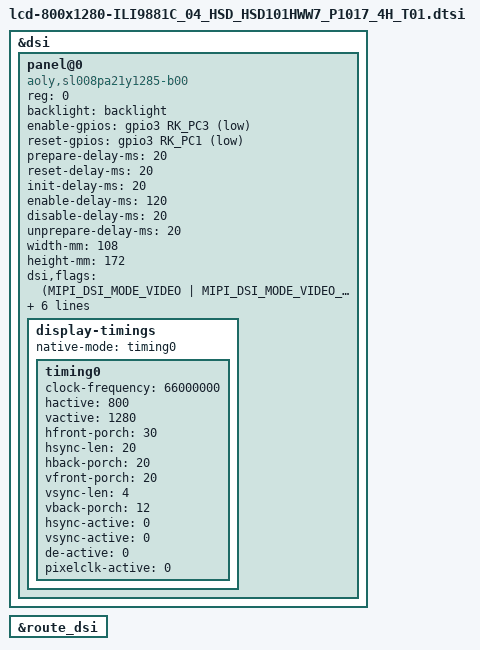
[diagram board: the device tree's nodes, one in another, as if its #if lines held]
&dsi {
	status = "okay";

	panel@0 {
		compatible = "aoly,sl008pa21y1285-b00", "simple-panel-dsi";
		reg = <0>;
		backlight = <&backlight>;
	//	power-supply = <&vcc5v0_host>;//vcc5v0_host  vcc3v3_lcd
	//	power-invert;
#if defined (DHTX_CFP3310M1A)
		enable-gpios = <&gpio3 RK_PC3 GPIO_ACTIVE_LOW>;
#else
		enable-gpios = <&gpio3 RK_PC0 GPIO_ACTIVE_HIGH>;
#endif
		reset-gpios = <&gpio3 RK_PC1 GPIO_ACTIVE_LOW>;
		prepare-delay-ms = <20>;
		reset-delay-ms = <20>;
		init-delay-ms = <20>;
		enable-delay-ms = <120>;
		disable-delay-ms = <20>;
		unprepare-delay-ms = <20>;

		width-mm = <108>;
		height-mm = <172>;

		dsi,flags = <(MIPI_DSI_MODE_VIDEO | MIPI_DSI_MODE_VIDEO_BURST |
			      MIPI_DSI_MODE_LPM | MIPI_DSI_MODE_EOT_PACKET)>;
		dsi,format = <MIPI_DSI_FMT_RGB888>;
		dsi,lanes = <4>;

		panel-init-sequence = [

39 00 04 FF 98 81 03    
15 00 02 01 00
15 00 02 02 00
15 00 02 03 53 
15 00 02 04 13 
15 00 02 05 00 
15 00 02 06 04 
15 00 02 07 00 
15 00 02 08 00 
15 00 02 09 22 
15 00 02 0a 22 
15 00 02 0b 00 
15 00 02 0c 01 
15 00 02 0d 00 
15 00 02 0e 00 
15 00 02 0f 23 
15 00 02 10 23 
15 00 02 11 00
15 00 02 12 00
15 00 02 13 00
15 00 02 14 00
15 00 02 15 00
15 00 02 16 00
15 00 02 17 00
15 00 02 18 00
15 00 02 19 00
15 00 02 1a 00
15 00 02 1b 00
15 00 02 1c 00
15 00 02 1d 00
15 00 02 1e 44
15 00 02 1f 80
15 00 02 20 02 
15 00 02 21 03 
15 00 02 22 00
15 00 02 23 00
15 00 02 24 00
15 00 02 25 00
15 00 02 26 00
15 00 02 27 00
15 00 02 28 33 
15 00 02 29 03 
15 00 02 2a 00 
15 00 02 2b 00 
15 00 02 2c 00 
15 00 02 2d 00 
15 00 02 2e 00 
15 00 02 2f 00 
15 00 02 30 00 
15 00 02 31 00 
15 00 02 32 00 
15 00 02 33 00 
15 00 02 34 04 
15 00 02 35 00 
15 00 02 36 00 
15 00 02 37 00 
15 00 02 38 3C 
15 00 02 39 00 
15 00 02 3a 40 
15 00 02 3b 40 
15 00 02 3c 00 
15 00 02 3d 00 
15 00 02 3e 00 
15 00 02 3f 00 
15 00 02 40 00 
15 00 02 41 00 
15 00 02 42 00 
15 00 02 43 00 
15 00 02 44 00 
15 00 02 50 01 
15 00 02 51 23 
15 00 02 52 45 
15 00 02 53 67 
15 00 02 54 89 
15 00 02 55 ab 
15 00 02 56 01 
15 00 02 57 23 
15 00 02 58 45 
15 00 02 59 67 
15 00 02 5a 89 
15 00 02 5b ab 
15 00 02 5c cd 
15 00 02 5d ef 
15 00 02 5e 11 
15 00 02 5f 01 
15 00 02 60 00 
15 00 02 61 15 
15 00 02 62 14 
15 00 02 63 0C 
15 00 02 64 0D 
15 00 02 65 0E 
15 00 02 66 0F 
15 00 02 67 06 
15 00 02 68 02 
15 00 02 69 02 
15 00 02 6a 02 
15 00 02 6b 02 
15 00 02 6c 02 
15 00 02 6d 02 
15 00 02 6e 08 
15 00 02 6f 02 
15 00 02 70 02 
15 00 02 71 02 
15 00 02 72 02 
15 00 02 73 02 
15 00 02 74 02 
15 00 02 75 01 
15 00 02 76 00 
15 00 02 77 15 
15 00 02 78 14 
15 00 02 79 0C 
15 00 02 7a 0D 
15 00 02 7b 0E 
15 00 02 7c 0F 
15 00 02 7D 08 
15 00 02 7E 02 
15 00 02 7F 02 
15 00 02 80 02 
15 00 02 81 02 
15 00 02 82 02 
15 00 02 83 02 
15 00 02 84 06 
15 00 02 85 02 
15 00 02 86 02 
15 00 02 87 02 
15 00 02 88 02 
15 00 02 89 02    
15 00 02 8A 02
39 00 04 FF 98 81 04
15 00 02 6C 15    
15 00 02 6E 3B    
15 00 02 6F 55    
15 00 02 3A 24    
15 00 02 8D 14    
15 00 02 87 BA    
15 00 02 26 76    
15 00 02 B2 D1    
15 00 02 B5 27    
15 00 02 31 75    
15 00 02 30 03    
15 00 02 3B 98    
15 00 02 35 1f    
15 00 02 33 14    
15 00 02 7A 0F
15 00 02 38 02
15 00 02 39 00
39 00 04 FF 98 81 01
15 00 02 22 0A	
15 00 02 31 0A	
15 00 02 35 07	
15 00 02 52 00	
15 00 02 53 53	
15 00 02 54 00	
15 00 02 55 59	
15 00 02 50 AC	
15 00 02 51 AA	
15 00 02 60 20	  
15 00 02 61 01
15 00 02 62 07	
15 00 02 63 00
15 00 02 A0 08
15 00 02 A1 19
15 00 02 A2 25
15 00 02 A3 11
15 00 02 A4 14
15 00 02 A5 26
15 00 02 A6 1A
15 00 02 A7 1C
15 00 02 A8 6C
15 00 02 A9 18
15 00 02 AA 23
15 00 02 AB 6C
15 00 02 AC 23
15 00 02 AD 25
15 00 02 AE 5B
15 00 02 AF 2C
15 00 02 B0 2E
15 00 02 B1 55
15 00 02 B2 61
15 00 02 B3 33
15 00 02 C0 08
15 00 02 C1 1A
15 00 02 C2 27
15 00 02 C3 11
15 00 02 C4 13
15 00 02 C5 26
15 00 02 C6 19
15 00 02 C7 1C
15 00 02 C8 6D
15 00 02 C9 17
15 00 02 CA 24
15 00 02 CB 6B
15 00 02 CC 23
15 00 02 CD 26
15 00 02 CE 5B
15 00 02 CF 2C
15 00 02 D0 2E
15 00 02 D1 55
15 00 02 D2 62
15 00 02 D3 33
39 00 04 FF 98 81 00
15 00 02   35  00 
05 78 01 11
05 14 01 29

		];

		panel-exit-sequence = [
			05 00 01 28
			05 00 01 10
		];

		display-timings {
			native-mode = <&timing0>;

			timing0: timing0 {
				clock-frequency = <66000000>;
				hactive = <800>;
				vactive = <1280>;//1068
				hfront-porch = <30>;
				hsync-len = <20>;
				hback-porch = <20>;
				vfront-porch = <20>;//124
				vsync-len = <4>;
				vback-porch = <12>;//116
				hsync-active = <0>;
				vsync-active = <0>;
				de-active = <0>;
				pixelclk-active = <0>;
			};
		};
	};
};


&route_dsi {
	status = "okay";
};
